# CH32F103xx register map
Vendor: WCH Ltd.; File version: 1.0
Registers are 32-bit, read-write, reset 0x0 unless marked. A register's access mark holds for its fields unless they carry their own. Offsets are from the block's base; [hi:lo] are bit positions; {n}, {i} and the like mark numbered series.

## PWR — Power control
Base 0x40007000
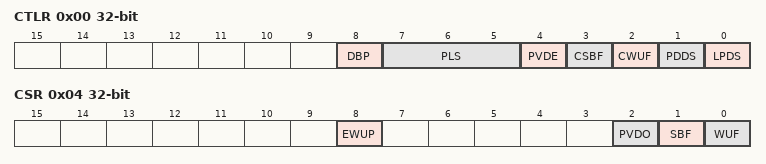
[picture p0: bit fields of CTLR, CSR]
0x00 CTLR — Power control register (PWR_CTRL)
  [8] DBP — Disable Backup Domain write protection
  [7:5] PLS — PVD Level Selection
  [4] PVDE — Power Voltage Detector Enable
  [3] CSBF — Clear STANDBY Flag
  [2] CWUF — Clear Wake-up Flag
  [1] PDDS — Power Down Deep Sleep
  [0] LPDS — Low Power Deep Sleep
0x04 CSR access per field — Power control register (PWR_CSR)
  [8] EWUP rw — Enable WKUP pin
  [2] PVDO ro — PVD Output
  [1] SBF ro — STANDBY Flag
  [0] WUF ro — Wake-Up Flag

## EXTEND — extension configuration
Base 0x40023800
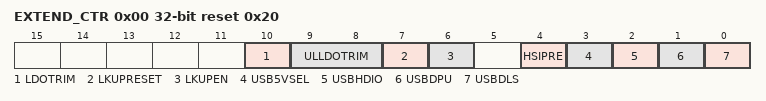
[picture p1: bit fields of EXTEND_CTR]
0x00 EXTEND_CTR reset 0x20 — EXTEND register
  [10] LDOTRIM
  [9:8] ULLDOTRIM
  [7] LKUPRESET — LOCKUP RESET
  [6] LKUPEN — LOCKUP
  [4] HSIPRE — Whether HSI is divided
  [3] USB5VSEL — USB 5V Enable
  [2] USBHDIO — USBHD IO(PB6/PB7) Enable
  [1] USBDPU — USBD pullup Enable
  [0] USBDLS — USBD Lowspeed Enable

## GPIOA — General purpose I/O
Base 0x40010800
Same registers: GPIOB 0x40010C00, GPIOC 0x40011000, GPIOD 0x40011400
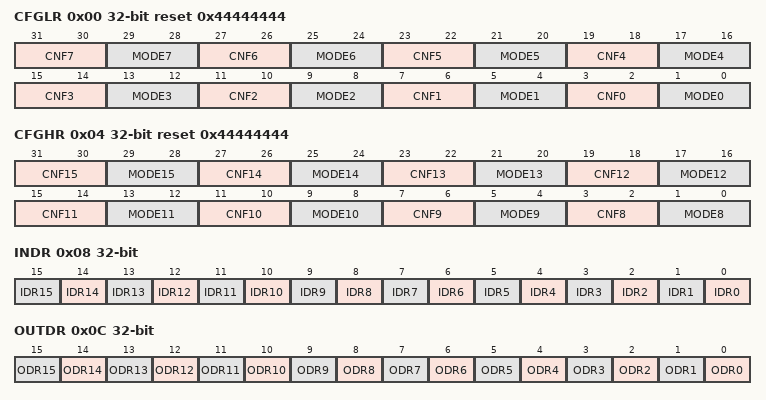
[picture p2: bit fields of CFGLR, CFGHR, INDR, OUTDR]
0x00 CFGLR reset 0x44444444 — Port configuration register low(GPIOn_CFGLR)
  [31:30] CNF7 — Port n.7 configuration bits
  [29:28] MODE7 — Port n.7 mode bits
  [27:26] CNF6 — Port n.6 configuration bits
  [25:24] MODE6 — Port n.6 mode bits
  [23:22] CNF5 — Port n.5 configuration bits
  [21:20] MODE5 — Port n.5 mode bits
  [19:18] CNF4 — Port n.4 configuration bits
  [17:16] MODE4 — Port n.4 mode bits
  [15:14] CNF3 — Port n.3 configuration bits
  [13:12] MODE3 — Port n.3 mode bits
  [11:10] CNF2 — Port n.2 configuration bits
  [9:8] MODE2 — Port n.2 mode bits
  [7:6] CNF1 — Port n.1 configuration bits
  [5:4] MODE1 — Port n.1 mode bits
  [3:2] CNF0 — Port n.0 configuration bits
  [1:0] MODE0 — Port n.0 mode bits
0x04 CFGHR reset 0x44444444 — Port configuration register high (GPIOn_CFGHR)
  [31:30] CNF15 — Port n.15 configuration bits
  [29:28] MODE15 — Port n.15 mode bits
  [27:26] CNF14 — Port n.14 configuration bits
  [25:24] MODE14 — Port n.14 mode bits
  [23:22] CNF13 — Port n.13 configuration bits
  [21:20] MODE13 — Port n.13 mode bits
  [19:18] CNF12 — Port n.12 configuration bits
  [17:16] MODE12 — Port n.12 mode bits
  [15:14] CNF11 — Port n.11 configuration bits
  [13:12] MODE11 — Port n.11 mode bits
  [11:10] CNF10 — Port n.10 configuration bits
  [9:8] MODE10 — Port n.10 mode bits
  [7:6] CNF9 — Port n.9 configuration bits
  [5:4] MODE9 — Port n.9 mode bits
  [3:2] CNF8 — Port n.8 configuration bits
  [1:0] MODE8 — Port n.8 mode bits
0x08 INDR ro — Port input data register (GPIOn_INDR)
  [n] IDR{n} (n=0..15) — Port input data
0x0C OUTDR — Port output data register (GPIOn_OUTDR)
  [n] ODR{n} (n=0..15) — Port output data
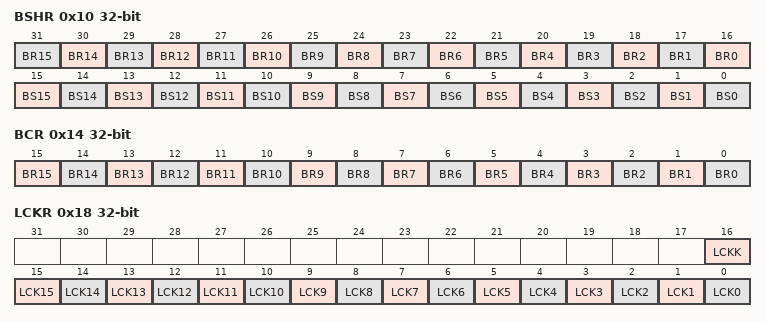
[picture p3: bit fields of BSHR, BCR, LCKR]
0x10 BSHR wo — Port bit set/reset register (GPIOn_BSHR)
  [n+16] BR{n} (n=0..15) — Reset bit {n}
  [n] BS{n} (n=3..15) — Set bit {n}
  [2] BS2 — Set bit 1
  [1] BS1 — Set bit 1
  [0] BS0 — Set bit 0
0x14 BCR wo — Port bit reset register (GPIOn_BCR)
  [n] BR{n} (n=3..15) — Reset bit {n}
  [2] BR2 — Reset bit 1
  [1] BR1 — Reset bit 1
  [0] BR0 — Reset bit 0
0x18 LCKR — Port configuration lock register
  [16] LCKK — Lock key
  [n] LCK{n} (n=0..15) — Port A Lock bit {n}

## AFIO — Alternate function I/O
Base 0x40010000
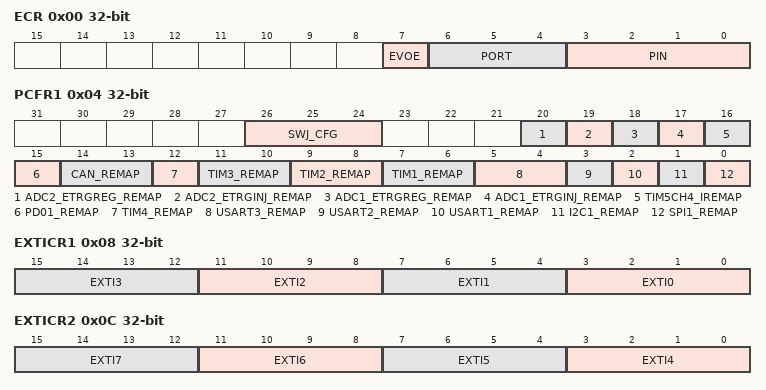
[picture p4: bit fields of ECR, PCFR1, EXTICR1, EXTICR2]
0x00 ECR — Event Control Register (AFIO_ECR)
  [7] EVOE — Event Output Enable
  [6:4] PORT — Port selection
  [3:0] PIN — Pin selection
0x04 PCFR1 access per field — AF remap and debug I/O configuration register (AFIO_PCFR1)
  [26:24] SWJ_CFG wo — Serial wire JTAG configuration
  [20] ADC2_ETRGREG_REMAP rw — ADC 2 external trigger regular conversion remapping
  [19] ADC2_ETRGINJ_REMAP rw — ADC 2 external trigger injected conversion remapping
  [18] ADC1_ETRGREG_REMAP rw — ADC 1 external trigger regular conversion remapping
  [17] ADC1_ETRGINJ_REMAP rw — ADC 1 External trigger injected conversion remapping
  [16] TIM5CH4_IREMAP rw — Set and cleared by software
  [15] PD01_REMAP rw — Port D0/Port D1 mapping on OSCIN/OSCOUT
  [14:13] CAN_REMAP rw — CAN1 remapping
  [12] TIM4_REMAP rw — TIM4 remapping
  [11:10] TIM3_REMAP rw — TIM3 remapping
  [9:8] TIM2_REMAP rw — TIM2 remapping
  [7:6] TIM1_REMAP rw — TIM1 remapping
  [5:4] USART3_REMAP rw — USART3 remapping
  [3] USART2_REMAP rw — USART2 remapping
  [2] USART1_REMAP rw — USART1 remapping
  [1] I2C1_REMAP rw — I2C1 remapping
  [0] SPI1_REMAP rw — SPI1 remapping
0x08 EXTICR1 — External interrupt configuration register 1 (AFIO_EXTICR1)
  [4n+3:4n] EXTI{n} (n=0..3) — EXTI{n} configuration
0x0C EXTICR2 — External interrupt configuration register 2 (AFIO_EXTICR2)
  [4n-13:4n-16] EXTI{n} (n=4..7) — EXTI{n} configuration
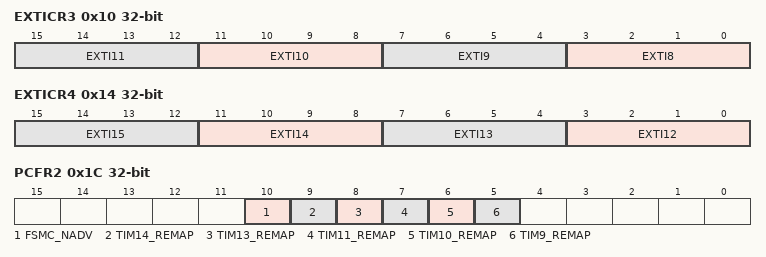
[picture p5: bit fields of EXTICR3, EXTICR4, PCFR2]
0x10 EXTICR3 — External interrupt configuration register 3 (AFIO_EXTICR3)
  [4n-29:4n-32] EXTI{n} (n=8..11) — EXTI{n} configuration
0x14 EXTICR4 — External interrupt configuration register 4 (AFIO_EXTICR4)
  [4n-45:4n-48] EXTI{n} (n=12..15) — EXTI{n} configuration
0x1C PCFR2 — AF remap and debug I/O configuration register
  [10] FSMC_NADV — NADV connect/disconnect
  [9] TIM14_REMAP — TIM14 remapping
  [8] TIM13_REMAP — TIM13 remapping
  [7] TIM11_REMAP — TIM11 remapping
  [6] TIM10_REMAP — TIM10 remapping
  [5] TIM9_REMAP — TIM9 remapping
